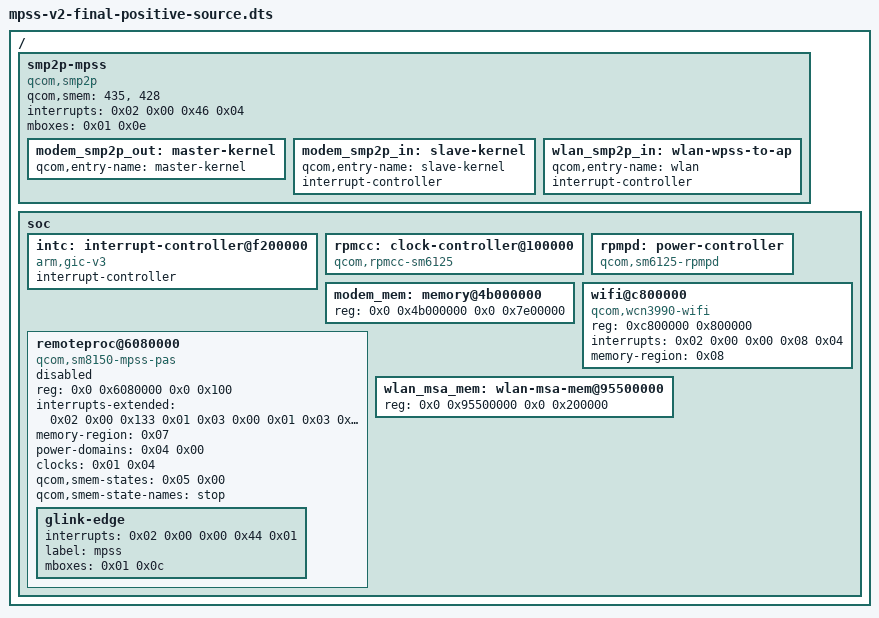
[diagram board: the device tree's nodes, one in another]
/dts-v1/;
/ {
    #address-cells = <2>;
    #size-cells = <2>;

    smp2p-mpss {
        compatible = "qcom,smp2p";
        qcom,smem = <435>, <428>;

        interrupts = <0x02 0x00 0x46 0x04>;
        mboxes = <0x01 0x0e>;

        modem_smp2p_out: master-kernel {
            qcom,entry-name = "master-kernel";
            #qcom,smem-state-cells = <1>;
            phandle = <0x05>;
        };

        modem_smp2p_in: slave-kernel {
            qcom,entry-name = "slave-kernel";
            interrupt-controller;
            #interrupt-cells = <0x02>;
            phandle = <0x03>;
        };

        wlan_smp2p_in: wlan-wpss-to-ap {
            qcom,entry-name = "wlan";
            interrupt-controller;
            #interrupt-cells = <0x02>;
            phandle = <0x06>;
        };
    };

    soc {
        #address-cells = <1>;
        #size-cells = <1>;

        intc: interrupt-controller@f200000 {
            compatible = "arm,gic-v3";
            #interrupt-cells = <0x03>;
            interrupt-controller;
            phandle = <0x02>;
        };

        rpmcc: clock-controller@100000 {
            compatible = "qcom,rpmcc-sm6125";
            #clock-cells = <1>;
            #mbox-cells = <1>;
            phandle = <0x01>;
        };

        rpmpd: power-controller {
            compatible = "qcom,sm6125-rpmpd";
            #power-domain-cells = <1>;
            phandle = <0x04>;
        };

        modem_mem: memory@4b000000 {
            reg = <0x0 0x4b000000 0x0 0x7e00000>;
            phandle = <0x07>;
        };

        remoteproc@6080000 {
            compatible = "qcom,sm8150-mpss-pas";
            reg = <0x0 0x6080000 0x0 0x100>;
            interrupts-extended = <0x02 0x00 0x133 0x01 0x03 0x00 0x01 0x03 0x01 0x01 0x03 0x02 0x01 0x03 0x03 0x01 0x03 0x07 0x01>;
            interrupt-names = "wdog", "fatal", "ready",
                              "handover", "stop-ack", "shutdown-ack";
            memory-region = <0x07>;
            power-domains = <0x04 0x00>;
            clocks = <0x01 0x04>;
            clock-names = "xo";
            qcom,smem-states = <0x05 0x00>;
            qcom,smem-state-names = "stop";
            status = "disabled";

            glink-edge {
                interrupts = <0x02 0x00 0x00 0x44 0x01>;
                label = "mpss";
                mboxes = <0x01 0x0c>;
            };
        };

        wifi@c800000 {
            compatible = "qcom,wcn3990-wifi";
            reg = <0xc800000 0x800000>;
            interrupts = <0x02 0x00 0x00 0x08 0x04>;
            memory-region = <0x08>;
            status = "okay";
        };

        wlan_msa_mem: wlan-msa-mem@95500000 {
            reg = <0x0 0x95500000 0x0 0x200000>;
            phandle = <0x08>;
        };
    };
};
